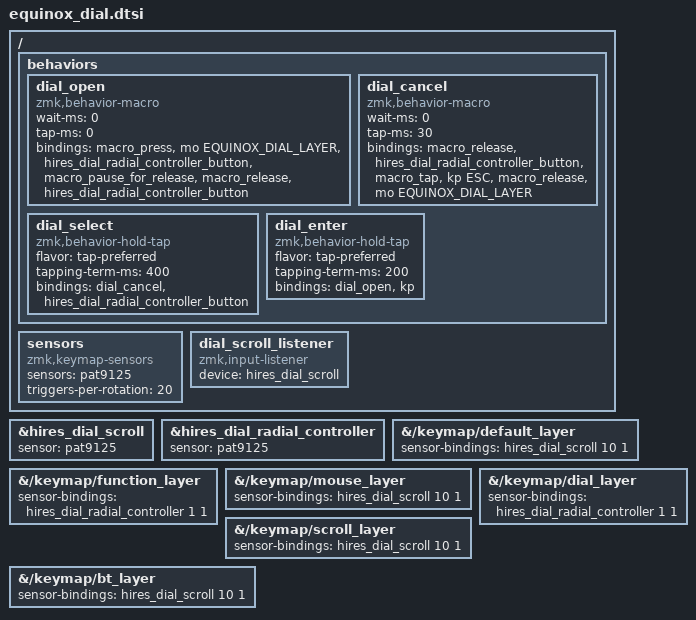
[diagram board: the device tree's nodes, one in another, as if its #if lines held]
/* Layer 5 latches dial routing independently of the momentary Fn layer. */
#define EQUINOX_DIAL_LAYER 5
/ {
    behaviors {
        dial_open: dial_open {
            compatible = "zmk,behavior-macro";
            #binding-cells = <0>;
            wait-ms = <0>;
            tap-ms = <0>;
            bindings = <&macro_press &mo EQUINOX_DIAL_LAYER &hires_dial_radial_controller_button>,
                       <&macro_pause_for_release>,
                       <&macro_release &hires_dial_radial_controller_button>;
        };
        dial_cancel: dial_cancel {
            compatible = "zmk,behavior-macro";
            #binding-cells = <0>;
            wait-ms = <0>;
            tap-ms = <30>;
            bindings = <&macro_release &hires_dial_radial_controller_button>,
                       <&macro_tap &kp ESC>,
                       <&macro_release &mo EQUINOX_DIAL_LAYER>;
        };
        dial_select: dial_select {
            compatible = "zmk,behavior-hold-tap";
            #binding-cells = <2>;
            flavor = "tap-preferred";
            tapping-term-ms = <400>;
            bindings = <&dial_cancel>, <&hires_dial_radial_controller_button>;
        };
        dial_enter: dial_enter {
            compatible = "zmk,behavior-hold-tap";
            #binding-cells = <2>;
            flavor = "tap-preferred";
            tapping-term-ms = <200>;
            bindings = <&dial_open>, <&kp>;
        };
    };
};

/* PAT is local to the left Central. Keep the right PMW split path unchanged. */
#if defined(EQUINOX_HAS_DIAL)

/ {
    sensors {
        compatible = "zmk,keymap-sensors";
        sensors = <&pat9125>;
        triggers-per-rotation = <20>;
    };
    dial_scroll_listener {
        compatible = "zmk,input-listener";
        device = <&hires_dial_scroll>;
    };
};

&hires_dial_scroll { sensor = <&pat9125>; };
&hires_dial_radial_controller { sensor = <&pat9125>; };

&{/keymap/default_layer} { sensor-bindings = <&hires_dial_scroll 10 1>; };
&{/keymap/function_layer} { sensor-bindings = <&hires_dial_radial_controller 1 1>; };
&{/keymap/mouse_layer} { sensor-bindings = <&hires_dial_scroll 10 1>; };
&{/keymap/scroll_layer} { sensor-bindings = <&hires_dial_scroll 10 1>; };
&{/keymap/bt_layer} { sensor-bindings = <&hires_dial_scroll 10 1>; };
&{/keymap/dial_layer} { sensor-bindings = <&hires_dial_radial_controller 1 1>; };
#endif
